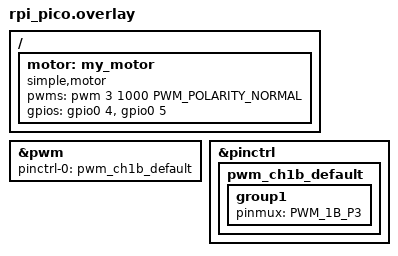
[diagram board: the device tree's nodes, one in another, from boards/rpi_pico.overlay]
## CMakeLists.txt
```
# Minimum CMake required version
cmake_minimum_required( VERSION 3.20.0 )

set(ZEPHYR_EXTRA_MODULES "${CMAKE_SOURCE_DIR}/drivers/simple_motor")
find_package(Zephyr REQUIRED HINTS $ENV{ZEPHYR_BASE})

# Project and source files
project(demo)
target_sources(app PRIVATE src/main.c)
```

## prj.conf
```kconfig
# Disable optimizations
CONFIG_NO_OPTIMIZATIONS=y
# Include GPIO drivers in system config (KCONFIG)
CONFIG_GPIO=y
CONFIG_PWM=y

# line below enables our device driver
CONFIG_SIMPLE_MOTOR=y
```

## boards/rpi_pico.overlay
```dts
 / {
 
    motor: my_motor{
        compatible = "simple,motor";
        pwms = <&pwm 3 1000 PWM_POLARITY_NORMAL>;
        gpios = <&gpio0 4 GPIO_ACTIVE_HIGH>, <&gpio0 5 GPIO_ACTIVE_HIGH>;
        
   

        /*zephyr,deferred-init;*/
 
  
 
        
  
    };
};

/* Enable and configure the PWM controller node */

&pwm {
    status = "okay";
    pinctrl-0 = <&pwm_ch1b_default>; /* Specific pin mux for RP2040 */
    pinctrl-names = "default";
};

&pinctrl {
    pwm_ch1b_default: pwm_ch1b_default {
        group1 {
            /* Pin 3 corresponds to GPIO3. Check your board's pinctrl file for exact syntax.
               For RP2040, this is often referenced as PWM_1B_P3 or similar. */
            pinmux = <PWM_1B_P3>; 
        };
    };
};
```

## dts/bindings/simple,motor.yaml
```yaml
# binding description
description: motor controller 2 pins

# binding name (this is the one will be used in the device tree file)
compatible: "simple,motor"

#child-binding:
  # properties our node will have, in our case there is just one called gpios
  # which will be mandatory and their values are in a multi type array
properties:

  gpios:
    type: phandle-array
    required: true
    description: The GPIO pin connected to a simple led.

  pwms:
    type: phandle-array
    required: true
    description: The GPIO pin connected to a simple led.

  zephyr,deferred-init:
    type: boolean
    description: |
      Do not initialize device automatically on boot. Device should be manually
      initialized using device_init().
```

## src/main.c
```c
/*
  build for rpi_pico only
  when i tried for maker_pi_rp2040
  i'm getting error on the overlay file even though it's for the same overlay
*/

#include <zephyr/kernel.h>
#include <zephyr/drivers/gpio.h>
#include <zephyr/drivers/pwm.h>
#include "simple_motor.h"

const struct device *motor_dev = DEVICE_DT_GET( DT_NODELABEL(motor) ); 

int main(void)
{   
    simple_motor_stop(motor_dev);
    while(true)
    {   
       simple_motor_forward(motor_dev);
       for(int i=0; i<10; i++) {simple_motor_set_speed(motor_dev, i); k_msleep(500);}

       k_msleep(500);
       simple_motor_reverse(motor_dev);
       simple_motor_set_speed(motor_dev, 5);//50 percent
       k_msleep(3000);       
       simple_motor_stop(motor_dev);
       simple_motor_set_speed(motor_dev, 1);
       k_msleep(3000); 
    }
        
	return 0;
}
```
